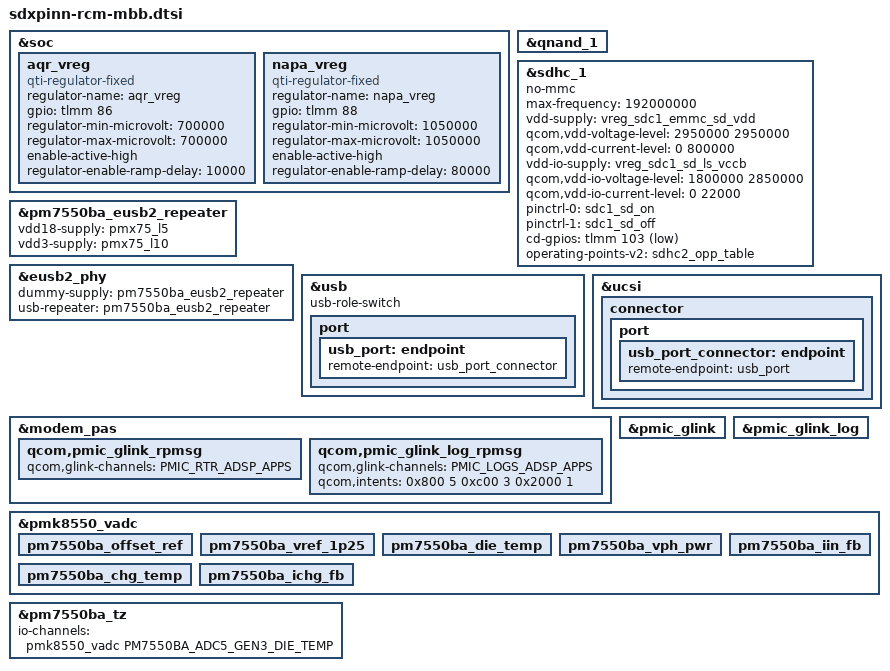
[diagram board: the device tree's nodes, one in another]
#include <dt-bindings/gpio/gpio.h>

#include "sdxpinn-pmic-overlay.dtsi"
#include "pm7550ba.dtsi"

&soc {
	aqr_vreg: aqr_vreg {
		compatible = "qti-regulator-fixed";
		regulator-name = "aqr_vreg";
		gpio = <&tlmm 86 GPIO_ACTIVE_HIGH>;
		regulator-min-microvolt = <700000>;
		regulator-max-microvolt = <700000>;
		enable-active-high;
		regulator-enable-ramp-delay = <10000>;
	};

	napa_vreg: napa_vreg {
		compatible = "qti-regulator-fixed";
		regulator-name = "napa_vreg";
		gpio = <&tlmm 88 GPIO_ACTIVE_HIGH>;
		regulator-min-microvolt = <1050000>;
		regulator-max-microvolt = <1050000>;
		enable-active-high;
		regulator-enable-ramp-delay = <80000>;
	};
};

&qnand_1 {
	status = "ok";
};

&sdhc_1 {
	status = "ok";

	no-mmc;
	max-frequency = <192000000>;

	vdd-supply = <&vreg_sdc1_emmc_sd_vdd>;
	qcom,vdd-voltage-level = <2950000 2950000>;
	qcom,vdd-current-level = <0 800000>;

	vdd-io-supply = <&vreg_sdc1_sd_ls_vccb>;
	qcom,vdd-io-voltage-level = <1800000 2850000>;
	qcom,vdd-io-current-level = <0 22000>;

	pinctrl-names = "default", "sleep";
	pinctrl-0 = <&sdc1_sd_on>;
	pinctrl-1 = <&sdc1_sd_off>;

	cd-gpios = <&tlmm 103 GPIO_ACTIVE_LOW>;

	operating-points-v2 = <&sdhc2_opp_table>;
};

&pm7550ba_eusb2_repeater {
	vdd18-supply = <&pmx75_l5>;
	vdd3-supply = <&pmx75_l10>;
	status = "ok";
};

&eusb2_phy {
	dummy-supply = <&pm7550ba_eusb2_repeater>;
	usb-repeater = <&pm7550ba_eusb2_repeater>;
};

&usb {
	usb-role-switch;
	port {
		usb_port: endpoint {
			remote-endpoint = <&usb_port_connector>;
		};
	};
};

&ucsi {
	connector {
		port {
			usb_port_connector: endpoint {
				remote-endpoint = <&usb_port>;
			};
		};
	};
};

&modem_pas {
	qcom,pmic_glink_rpmsg {
		qcom,glink-channels = "PMIC_RTR_ADSP_APPS";
	};

	qcom,pmic_glink_log_rpmsg {
		qcom,glink-channels = "PMIC_LOGS_ADSP_APPS";
		qcom,intents = <0x800 5
				0xc00 3
				0x2000 1>;
	};
};

&pmic_glink {
	status = "ok";
};

&pmic_glink_log {
	status = "ok";
};

&pmk8550_vadc {
	/* PM8550BA Channel nodes */
	pm7550ba_offset_ref {
		status = "ok";
	};

	pm7550ba_vref_1p25 {
		status = "ok";
	};

	pm7550ba_die_temp {
		status = "ok";
	};

	pm7550ba_vph_pwr {
		status = "ok";
	};

	pm7550ba_chg_temp {
		status = "ok";
	};

	pm7550ba_iin_fb {
		status = "ok";
	};

	pm7550ba_ichg_fb {
		status = "ok";
	};
};

&pm7550ba_tz {
	io-channels = <&pmk8550_vadc PM7550BA_ADC5_GEN3_DIE_TEMP>;
	io-channel-names = "thermal";
};
